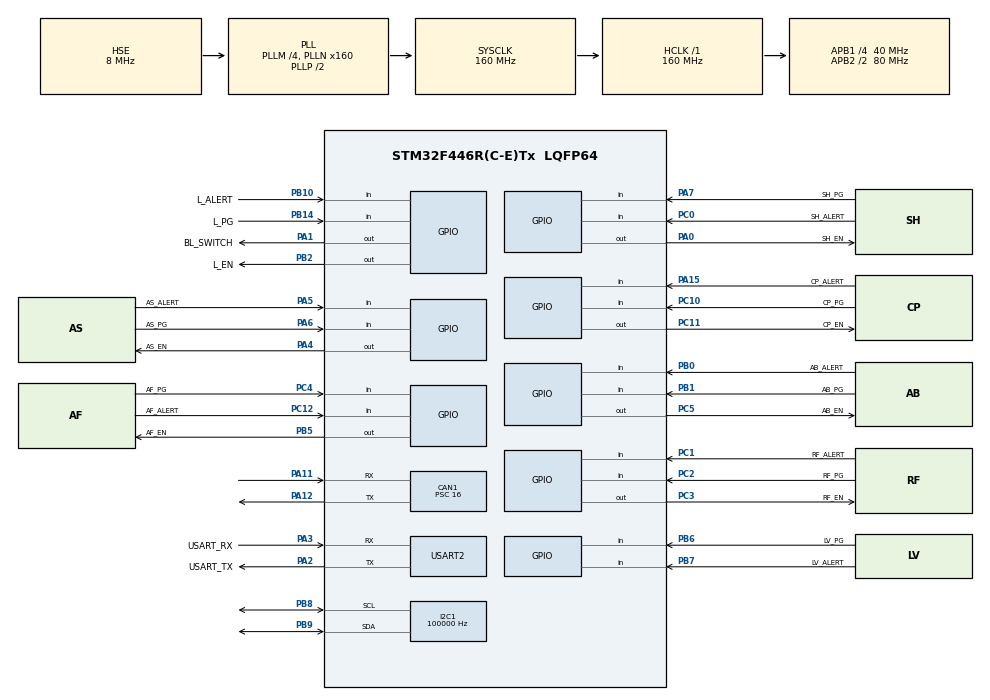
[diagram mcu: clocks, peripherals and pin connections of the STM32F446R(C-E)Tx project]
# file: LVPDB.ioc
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CAN1.BS1=CAN_BS1_3TQ
CAN1.CalculateBaudRate=500000
CAN1.CalculateTimeBit=2000
CAN1.CalculateTimeQuantum=400.0
CAN1.Prescaler=16
I2C1.ClockSpeed=100000
I2C1.I2C_Mode=I2C_Standard
Mcu.Family=STM32F4
Mcu.Name=STM32F446R(C-E)Tx
Mcu.Package=LQFP64
NVIC.CAN1_RX0_IRQn=true\:0\:0\:false\:false\:true\:true\:true\:true
NVIC.CAN1_RX1_IRQn=true\:0\:0\:false\:false\:true\:true\:true\:true
NVIC.PriorityGroup=NVIC_PRIORITYGROUP_0
NVIC.TIM1_UP_TIM10_IRQn=true\:0\:0\:false\:false\:true\:true\:true\:true
PA0-WKUP.GPIO_Label=SH_EN
PA0-WKUP.Signal=GPIO_Output
PA1.GPIO_Label=BL_SWITCH
PA1.GPIO_PuPd=GPIO_NOPULL
PA1.PinState=GPIO_PIN_RESET
PA1.Signal=GPIO_Output
PA11.Mode=CAN_Activate
PA11.Signal=CAN1_RX
PA12.Mode=CAN_Activate
PA12.Signal=CAN1_TX
PA15.GPIO_Label=CP_ALERT
PA15.Signal=GPIO_Input
PA2.GPIO_Label=USART_TX
PA2.Mode=Asynchronous
PA2.Signal=USART2_TX
PA3.GPIO_Label=USART_RX
PA3.Mode=Asynchronous
PA3.Signal=USART2_RX
PA4.GPIO_Label=AS_EN
PA4.Signal=GPIO_Output
PA5.GPIO_Label=AS_ALERT
PA5.Signal=GPIO_Input
PA6.GPIO_Label=AS_PG
PA6.Signal=GPIO_Input
PA7.GPIO_Label=SH_PG
PA7.Signal=GPIO_Input
PB0.GPIO_Label=AB_ALERT
PB0.Signal=GPIO_Input
PB1.GPIO_Label=AB_PG
PB1.Signal=GPIO_Input
PB10.GPIO_Label=L_ALERT
PB10.Signal=GPIO_Input
PB14.GPIO_Label=L_PG
PB14.Signal=GPIO_Input
PB2.GPIO_Label=L_EN
PB2.Signal=GPIO_Output
PB5.GPIO_Label=AF_EN
PB5.Signal=GPIO_Output
PB6.GPIO_Label=LV_PG
PB6.Signal=GPIO_Input
PB7.GPIO_Label=LV_ALERT
PB7.Signal=GPIO_Input
PB8.Mode=I2C
PB8.Signal=I2C1_SCL
PB9.Mode=I2C
PB9.Signal=I2C1_SDA
PC0.GPIO_Label=SH_ALERT
PC0.Signal=GPIO_Input
PC1.GPIO_Label=RF_ALERT
PC1.Signal=GPIO_Input
PC10.GPIO_Label=CP_PG
PC10.Signal=GPIO_Input
PC11.GPIO_Label=CP_EN
PC11.Signal=GPIO_Output
PC12.GPIO_Label=AF_ALERT
PC12.Signal=GPIO_Input
PC14-OSC32_IN.Mode=LSE-External-Oscillator
PC14-OSC32_IN.Signal=RCC_OSC32_IN
PC15-OSC32_OUT.Mode=LSE-External-Oscillator
PC15-OSC32_OUT.Signal=RCC_OSC32_OUT
PC2.GPIO_Label=RF_PG
PC2.Signal=GPIO_Input
PC3.GPIO_Label=RF_EN
PC3.Signal=GPIO_Output
PC4.GPIO_Label=AF_PG
PC4.Signal=GPIO_Input
PC5.GPIO_Label=AB_EN
PC5.Signal=GPIO_Output
PH0-OSC_IN.Mode=HSE-External-Oscillator
PH0-OSC_IN.Signal=RCC_OSC_IN
PH1-OSC_OUT.Mode=HSE-External-Oscillator
PH1-OSC_OUT.Signal=RCC_OSC_OUT
ProjectManager.HeapSize=0x200
ProjectManager.StackSize=0x400
ProjectManager.TargetToolchain=STM32CubeIDE
RCC.48MHZClocksFreq_Value=84000000
RCC.AHBFreq_Value=160000000
RCC.APB1CLKDivider=RCC_HCLK_DIV4
RCC.APB1Freq_Value=40000000
RCC.APB1TimFreq_Value=80000000
RCC.APB2CLKDivider=RCC_HCLK_DIV2
RCC.APB2Freq_Value=80000000
RCC.APB2TimFreq_Value=160000000
RCC.CortexFreq_Value=160000000
RCC.FLatency-AdvancedSettings=FLASH_LATENCY_5
RCC.HCLKFreq_Value=160000000
RCC.HSE_VALUE=8000000
RCC.HSI_VALUE=16000000
RCC.PLLM=4
RCC.PLLN=160
RCC.PLLSourceVirtual=RCC_PLLSOURCE_HSE
RCC.SYSCLKFreq_VALUE=160000000
RCC.SYSCLKSource=RCC_SYSCLKSOURCE_PLLCLK
RCC.USBFreq_Value=160000000
RCC.VCOOutputFreq_Value=320000000
TIM1.AutoReloadPreload=TIM_AUTORELOAD_PRELOAD_ENABLE
TIM1.CounterMode=TIM_COUNTERMODE_UP
TIM1.Period=10000-1
TIM1.Prescaler=160*100-1
USART2.Parity=PARITY_NONE
USART2.VirtualMode=VM_ASYNC
VP_TIM1_VS_ClockSourceINT.Mode=Internal
board=NUCLEO-F446RE

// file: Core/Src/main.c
/* USER CODE BEGIN Header */
/**
  ******************************************************************************
  * @file           : main.c
  * @brief          : Main program body
  ******************************************************************************
  * @attention
  *
  * Copyright (c) 2023 STMicroelectronics.
  * All rights reserved.
  *
  * This software is licensed under terms that can be found in the LICENSE file
  * in the root directory of this software component.
  * If no LICENSE file comes with this software, it is provided AS-IS.
  *
  ******************************************************************************
  */
/* USER CODE END Header */
#include "main.h"

CAN_HandleTypeDef hcan1;

I2C_HandleTypeDef hi2c1;

TIM_HandleTypeDef htim1;

UART_HandleTypeDef huart2;

void SystemClock_Config(void);
static void MX_GPIO_Init(void);
static void MX_USART2_UART_Init(void);
static void MX_I2C1_Init(void);
static void MX_CAN1_Init(void);
static void MX_TIM1_Init(void);

int main(void)
{

  /* MCU Configuration--------------------------------------------------------*/

  /* Reset of all peripherals, Initializes the Flash interface and the Systick. */
  HAL_Init();

  /* Configure the system clock */
  SystemClock_Config();

  /* Initialize all configured peripherals */
  MX_GPIO_Init();
  MX_USART2_UART_Init();
  MX_I2C1_Init();
  MX_CAN1_Init();
  MX_TIM1_Init();
  /* USER CODE BEGIN 2 */

  FEB_Main_Setup();

  /* USER CODE END 2 */

  /* Infinite loop */
  /* USER CODE BEGIN WHILE */
  while (1)
  {
	FEB_Main_Loop();
    /* USER CODE END WHILE */

  }
}

void SystemClock_Config(void)
{
  RCC_OscInitTypeDef RCC_OscInitStruct = {0};
  RCC_ClkInitTypeDef RCC_ClkInitStruct = {0};

  /** Configure the main internal regulator output voltage
  */
  __HAL_RCC_PWR_CLK_ENABLE();
  __HAL_PWR_VOLTAGESCALING_CONFIG(PWR_REGULATOR_VOLTAGE_SCALE1);

  /** Initializes the RCC Oscillators according to the specified parameters
  * in the RCC_OscInitTypeDef structure.
  */
  RCC_OscInitStruct.OscillatorType = RCC_OSCILLATORTYPE_HSE;
  RCC_OscInitStruct.HSEState = RCC_HSE_ON;
  RCC_OscInitStruct.PLL.PLLState = RCC_PLL_ON;
  RCC_OscInitStruct.PLL.PLLSource = RCC_PLLSOURCE_HSE;
  RCC_OscInitStruct.PLL.PLLM = 4;
  RCC_OscInitStruct.PLL.PLLN = 160;
  RCC_OscInitStruct.PLL.PLLP = RCC_PLLP_DIV2;
  RCC_OscInitStruct.PLL.PLLQ = 2;
  RCC_OscInitStruct.PLL.PLLR = 2;
  if (HAL_RCC_OscConfig(&RCC_OscInitStruct) != HAL_OK)
  {
    Error_Handler();
  }

  /** Initializes the CPU, AHB and APB buses clocks
  */
  RCC_ClkInitStruct.ClockType = RCC_CLOCKTYPE_HCLK|RCC_CLOCKTYPE_SYSCLK
                              |RCC_CLOCKTYPE_PCLK1|RCC_CLOCKTYPE_PCLK2;
  RCC_ClkInitStruct.SYSCLKSource = RCC_SYSCLKSOURCE_PLLCLK;
  RCC_ClkInitStruct.AHBCLKDivider = RCC_SYSCLK_DIV1;
  RCC_ClkInitStruct.APB1CLKDivider = RCC_HCLK_DIV4;
  RCC_ClkInitStruct.APB2CLKDivider = RCC_HCLK_DIV2;

  if (HAL_RCC_ClockConfig(&RCC_ClkInitStruct, FLASH_LATENCY_5) != HAL_OK)
  {
    Error_Handler();
  }
}

static void MX_CAN1_Init(void)
{

  hcan1.Instance = CAN1;
  hcan1.Init.Prescaler = 16;
  hcan1.Init.Mode = CAN_MODE_NORMAL;
  hcan1.Init.SyncJumpWidth = CAN_SJW_1TQ;
  hcan1.Init.TimeSeg1 = CAN_BS1_3TQ;
  hcan1.Init.TimeSeg2 = CAN_BS2_1TQ;
  hcan1.Init.TimeTriggeredMode = DISABLE;
  hcan1.Init.AutoBusOff = DISABLE;
  hcan1.Init.AutoWakeUp = DISABLE;
  hcan1.Init.AutoRetransmission = DISABLE;
  hcan1.Init.ReceiveFifoLocked = DISABLE;
  hcan1.Init.TransmitFifoPriority = DISABLE;
  if (HAL_CAN_Init(&hcan1) != HAL_OK)
  {
    Error_Handler();
  }

}

static void MX_I2C1_Init(void)
{

  hi2c1.Instance = I2C1;
  hi2c1.Init.ClockSpeed = 100000;
  hi2c1.Init.DutyCycle = I2C_DUTYCYCLE_2;
  hi2c1.Init.OwnAddress1 = 0;
  hi2c1.Init.AddressingMode = I2C_ADDRESSINGMODE_7BIT;
  hi2c1.Init.DualAddressMode = I2C_DUALADDRESS_DISABLE;
  hi2c1.Init.OwnAddress2 = 0;
  hi2c1.Init.GeneralCallMode = I2C_GENERALCALL_DISABLE;
  hi2c1.Init.NoStretchMode = I2C_NOSTRETCH_DISABLE;
  if (HAL_I2C_Init(&hi2c1) != HAL_OK)
  {
    Error_Handler();
  }

}

static void MX_TIM1_Init(void)
{

  TIM_ClockConfigTypeDef sClockSourceConfig = {0};
  TIM_MasterConfigTypeDef sMasterConfig = {0};

  htim1.Instance = TIM1;
  htim1.Init.Prescaler = 160*100-1;
  htim1.Init.CounterMode = TIM_COUNTERMODE_UP;
  htim1.Init.Period = 10000-1;
  htim1.Init.ClockDivision = TIM_CLOCKDIVISION_DIV1;
  htim1.Init.RepetitionCounter = 0;
  htim1.Init.AutoReloadPreload = TIM_AUTORELOAD_PRELOAD_ENABLE;
  if (HAL_TIM_Base_Init(&htim1) != HAL_OK)
  {
    Error_Handler();
  }
  sClockSourceConfig.ClockSource = TIM_CLOCKSOURCE_INTERNAL;
  if (HAL_TIM_ConfigClockSource(&htim1, &sClockSourceConfig) != HAL_OK)
  {
    Error_Handler();
  }
  sMasterConfig.MasterOutputTrigger = TIM_TRGO_RESET;
  sMasterConfig.MasterSlaveMode = TIM_MASTERSLAVEMODE_DISABLE;
  if (HAL_TIMEx_MasterConfigSynchronization(&htim1, &sMasterConfig) != HAL_OK)
  {
    Error_Handler();
  }

}

static void MX_USART2_UART_Init(void)
{

  huart2.Instance = USART2;
  huart2.Init.BaudRate = 115200;
  huart2.Init.WordLength = UART_WORDLENGTH_8B;
  huart2.Init.StopBits = UART_STOPBITS_1;
  huart2.Init.Parity = UART_PARITY_NONE;
  huart2.Init.Mode = UART_MODE_TX_RX;
  huart2.Init.HwFlowCtl = UART_HWCONTROL_NONE;
  huart2.Init.OverSampling = UART_OVERSAMPLING_16;
  if (HAL_UART_Init(&huart2) != HAL_OK)
  {
    Error_Handler();
  }

}

static void MX_GPIO_Init(void)
{
  GPIO_InitTypeDef GPIO_InitStruct = {0};

  /* GPIO Ports Clock Enable */
  __HAL_RCC_GPIOC_CLK_ENABLE();
  __HAL_RCC_GPIOH_CLK_ENABLE();
  __HAL_RCC_GPIOA_CLK_ENABLE();
  __HAL_RCC_GPIOB_CLK_ENABLE();

  /*Configure GPIO pin Output Level */
  HAL_GPIO_WritePin(GPIOC, RF_EN_Pin|AB_EN_Pin|CP_EN_Pin, GPIO_PIN_RESET);

  /*Configure GPIO pin Output Level */
  HAL_GPIO_WritePin(GPIOA, SH_EN_Pin|BL_SWITCH_Pin|AS_EN_Pin, GPIO_PIN_RESET);

  /*Configure GPIO pin Output Level */
  HAL_GPIO_WritePin(GPIOB, L_EN_Pin|AF_EN_Pin, GPIO_PIN_RESET);

  /*Configure GPIO pins : SH_ALERT_Pin RF_ALERT_Pin RF_PG_Pin AF_PG_Pin
                           CP_PG_Pin AF_ALERT_Pin */
  GPIO_InitStruct.Pin = SH_ALERT_Pin|RF_ALERT_Pin|RF_PG_Pin|AF_PG_Pin
                          |CP_PG_Pin|AF_ALERT_Pin;
  GPIO_InitStruct.Mode = GPIO_MODE_INPUT;
  GPIO_InitStruct.Pull = GPIO_NOPULL;
  HAL_GPIO_Init(GPIOC, &GPIO_InitStruct);

  /*Configure GPIO pins : RF_EN_Pin AB_EN_Pin CP_EN_Pin */
  GPIO_InitStruct.Pin = RF_EN_Pin|AB_EN_Pin|CP_EN_Pin;
  GPIO_InitStruct.Mode = GPIO_MODE_OUTPUT_PP;
  GPIO_InitStruct.Pull = GPIO_NOPULL;
  GPIO_InitStruct.Speed = GPIO_SPEED_FREQ_LOW;
  HAL_GPIO_Init(GPIOC, &GPIO_InitStruct);

  /*Configure GPIO pins : SH_EN_Pin BL_SWITCH_Pin AS_EN_Pin */
  GPIO_InitStruct.Pin = SH_EN_Pin|BL_SWITCH_Pin|AS_EN_Pin;
  GPIO_InitStruct.Mode = GPIO_MODE_OUTPUT_PP;
  GPIO_InitStruct.Pull = GPIO_NOPULL;
  GPIO_InitStruct.Speed = GPIO_SPEED_FREQ_LOW;
  HAL_GPIO_Init(GPIOA, &GPIO_InitStruct);

  /*Configure GPIO pins : AS_ALERT_Pin AS_PG_Pin SH_PG_Pin CP_ALERT_Pin */
  GPIO_InitStruct.Pin = AS_ALERT_Pin|AS_PG_Pin|SH_PG_Pin|CP_ALERT_Pin;
  GPIO_InitStruct.Mode = GPIO_MODE_INPUT;
  GPIO_InitStruct.Pull = GPIO_NOPULL;
  HAL_GPIO_Init(GPIOA, &GPIO_InitStruct);

  /*Configure GPIO pins : AB_ALERT_Pin AB_PG_Pin L_ALERT_Pin L_PG_Pin
                           LV_PG_Pin LV_ALERT_Pin */
  GPIO_InitStruct.Pin = AB_ALERT_Pin|AB_PG_Pin|L_ALERT_Pin|L_PG_Pin
                          |LV_PG_Pin|LV_ALERT_Pin;
  GPIO_InitStruct.Mode = GPIO_MODE_INPUT;
  GPIO_InitStruct.Pull = GPIO_NOPULL;
  HAL_GPIO_Init(GPIOB, &GPIO_InitStruct);

  /*Configure GPIO pins : L_EN_Pin AF_EN_Pin */
  GPIO_InitStruct.Pin = L_EN_Pin|AF_EN_Pin;
  GPIO_InitStruct.Mode = GPIO_MODE_OUTPUT_PP;
  GPIO_InitStruct.Pull = GPIO_NOPULL;
  GPIO_InitStruct.Speed = GPIO_SPEED_FREQ_LOW;
  HAL_GPIO_Init(GPIOB, &GPIO_InitStruct);

}

/* USER CODE BEGIN 4 */
void HAL_TIM_PeriodElapsedCallback(TIM_HandleTypeDef *htim) {
    if ( htim == &htim1 ) { // 1 ms timer callback
    	FEB_1ms_Callback();
    }
}
/* USER CODE END 4 */

void Error_Handler(void)
{
  __disable_irq();
  while (1)
  {
  }
}
